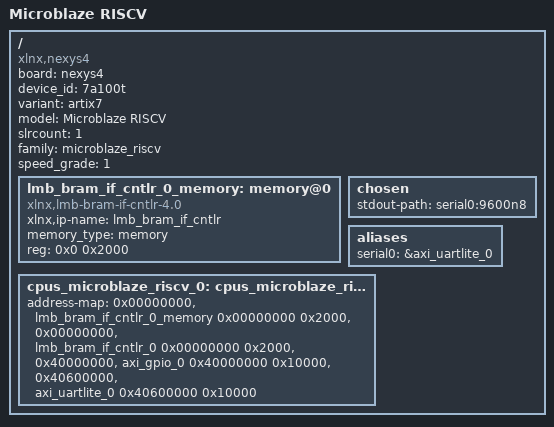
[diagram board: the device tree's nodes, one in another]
/dts-v1/;
#include "pl.dtsi"
/ {
	board = "nexys4";
	compatible = "xlnx,nexys4";
	device_id = "7a100t";
	#address-cells = <1>;
	variant = "artix7";
	model = "Microblaze RISCV";
	#size-cells = <1>;
	slrcount = <1>;
	family = "microblaze_riscv";
	speed_grade = "1";
	lmb_bram_if_cntlr_0_memory: memory@0 {
		compatible = "xlnx,lmb-bram-if-cntlr-4.0";
		xlnx,ip-name = "lmb_bram_if_cntlr";
		device_type = "memory";
		memory_type = "memory";
		reg = <0x0 0x2000>;
	};
	chosen {
		stdout-path = "serial0:9600n8";
	};
	aliases {
		serial0 = &axi_uartlite_0;
	};
	cpus_microblaze_riscv_0: cpus_microblaze_riscv@0 {
		address-map = <0x00000000 &lmb_bram_if_cntlr_0_memory 0x00000000 0x2000>, 
			      <0x00000000 &lmb_bram_if_cntlr_0 0x00000000 0x2000>, 
			      <0x40000000 &axi_gpio_0 0x40000000 0x10000>, 
			      <0x40600000 &axi_uartlite_0 0x40600000 0x10000>;
		#ranges-address-cells = <0x1>;
		#ranges-size-cells = <0x1>;
	};
};
